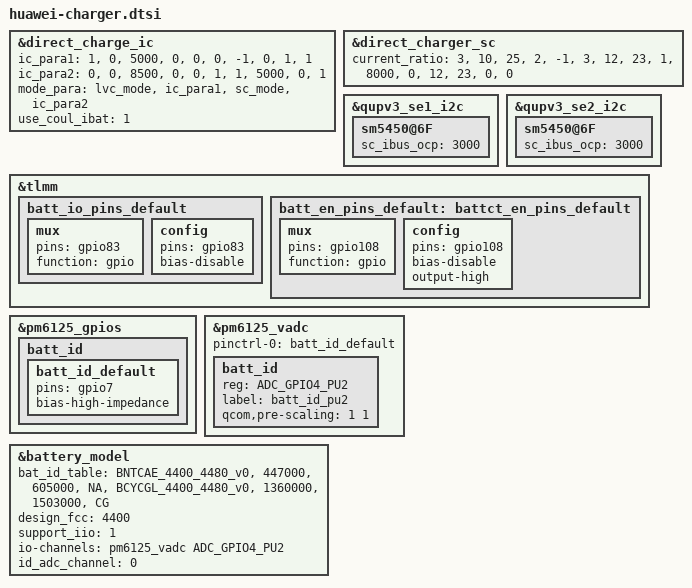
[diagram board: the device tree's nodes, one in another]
&direct_charge_ic {
	/* ic_index  path_index  max_ibat  ibat_sample_point  vbat_sample_point */
	ic_para1 =
		"1", "0", "5000", "0", "0",
		"0", "-1", "0", "1", "1";
	ic_para2 =
		"0", "0", "8500", "0", "0",
		"1", "1", "5000", "0", "1";
	mode_para =
		"lvc_mode", "ic_para1",
		"sc_mode", "ic_para2";
        use_coul_ibat = <1>;
	status = "ok";
};

&direct_charger_sc {
	current_ratio =
		"3", "10", "25", "2", "-1",
		"3", "12", "23", "1", "8000",
		"0", "12", "23", "0", "0";
};

&qupv3_se1_i2c {
	sm5450@6F {
		sc_ibus_ocp = <3000>;
	};
};

&qupv3_se2_i2c {
	sm5450@6F {
		sc_ibus_ocp = <3000>;
	};
};

&tlmm {
       batt_io_pins_default: batt_io_pins_default {
               mux {
                       pins = "gpio83";
                       function = "gpio";
               };
               config {
                       pins = "gpio83";
                       bias-disable;
               };
       };

       batt_en_pins_default: battct_en_pins_default {
               mux {
                       pins = "gpio108";
                       function = "gpio";
               };
               config {
                       pins = "gpio108";
                       bias-disable;
                       output-high;
               };
       };
};

&pm6125_gpios {
       batt_id {
               batt_id_default: batt_id_default {
                       pins = "gpio7";
                       bias-high-impedance;
               };
       };
};

&pm6125_vadc {
       pinctrl-0 = <&batt_id_default>;

       batt_id {
               reg = <ADC_GPIO4_PU2>;
               label = "batt_id_pu2";
               qcom,pre-scaling = <1 1>;
       };
};

&battery_model {
       bat_id_table =
               "BNTCAE_4400_4480_v0", "447000", "605000", "NA",
               "BCYCGL_4400_4480_v0", "1360000", "1503000", "CG";
       design_fcc = <4400>;
       support_iio = <1>;
       io-channels = <&pm6125_vadc ADC_GPIO4_PU2>;
       io-channel-names = "batt-id";
       id_adc_channel = <0>; /* useless but necessary for Qcom, set 0 as default */
       status = "ok";
};
